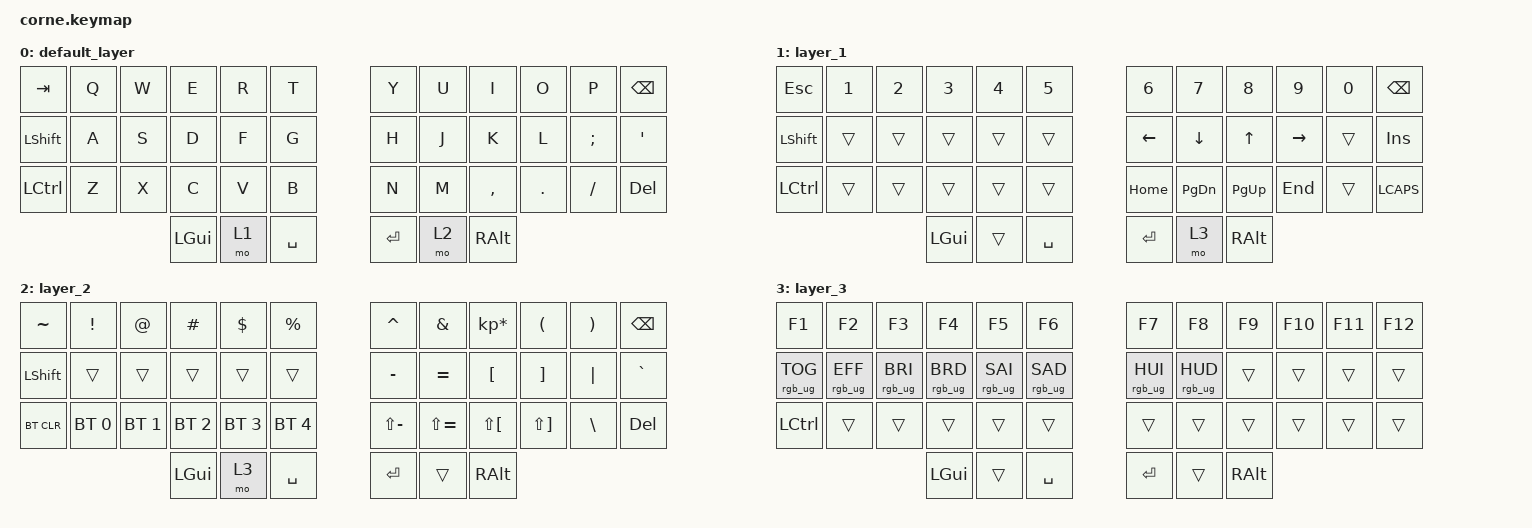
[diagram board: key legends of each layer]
/*
 * Copyright (c) 2020 The ZMK Contributors
 *
 * SPDX-License-Identifier: MIT
 */

#include <behaviors.dtsi>
#include <dt-bindings/zmk/keys.h>
#include <dt-bindings/zmk/bt.h>
#include <dt-bindings/zmk/rgb.h>

/ {
        keymap {
                compatible = "zmk,keymap";

                default_layer {
// -----------------------------------------------------------------------------------------
// | TAB  |  Q  |  W  |  E  |  R  |  T  |   |  Y  |  U   |  I  |  O  |  P  | BKSP |
// | SHFT |  A  |  S  |  D  |  F  |  G  |   |  H  |  J   |  K  |  L  |  ;  |  '   |
// | CTRL |  Z  |  X  |  C  |  V  |  B  |   |  N  |  M   |  ,  |  .  |  /  | DEL  |
//                    | GUI | LWR | SPC |   | ENT | RSE  | ALT |
                        bindings = <
   &kp TAB   &kp Q &kp W &kp E &kp R &kp T   &kp Y &kp U  &kp I     &kp O   &kp P    &kp BSPC
   &kp LSHFT &kp A &kp S &kp D &kp F &kp G   &kp H &kp J  &kp K     &kp L   &kp SEMI &kp SQT
   &kp LCTRL &kp Z &kp X &kp C &kp V &kp B   &kp N &kp M  &kp COMMA &kp DOT &kp FSLH &kp DEL
                  &kp LGUI &mo 1 &kp SPACE   &kp RET &mo 2 &kp RALT
                        >;
                };
                layer_1 {
// -----------------------------------------------------------------------------------------
// | ESC  |  1  |  2  |  3  |  4  |  5  |   |  6  |  7  |  8  |  9  |  0  | BKSP |
// | SHFT |     |     |     |     |     |   | LFT | DWN |  UP | RGT |     | INS  |
// | CTRL |     |     |     |     |     |   | HOME|PG_DN|PG_UP| END |     | LCAPS|
//                    | GUI |     | SPC |   | ENT |  L3 | ALT |
                        bindings = <
   &kp ESC    &kp N1       &kp N2       &kp N3       &kp N4       &kp N5     &kp N6    &kp N7    &kp N8    &kp N9    &kp N0 &kp BSPC
   &kp LSHFT  &trans       &trans       &trans       &trans       &trans     &kp LEFT  &kp DOWN  &kp UP    &kp RIGHT &trans &kp INS
   &kp LCTRL  &trans       &trans       &trans       &trans       &trans     &kp HOME  &kp PG_DN &kp PG_UP &kp END   &trans &kp LCAPS
                                        &kp LGUI     &trans       &kp SPACE  &kp RET   &mo 3     &kp RALT
                        >;
                };

                layer_2 {
// -----------------------------------------------------------------------------------------
// | ESC  |  !  |  @  |  #  |  $  |  %  |   |  ^  |  &  |  *  |  (  |  )  | BKSP |
// | SHFT |     |     |     |     |     |   |  -  |  =  |  {  |  }  | "|" |  `   |
// | BTCLR| BT1 | BT2 | BT3 | BT4 | BT5 |   |  _  |  +  |  [  |  ]  |  \  |  ~   | // TODO: Fix this row when &mkp is committed
//                    | GUI |  L3 | SPC |   | ENT |     | ALT |
                        bindings = <
   &kp TILDE  &kp EXCL     &kp AT       &kp HASH     &kp DLLR     &kp PRCNT         &kp CARET       &kp AMPS      &kp KP_MULTIPLY &kp LPAR    &kp RPAR &kp BSPC
   &kp LSHFT  &trans       &trans       &trans       &trans       &trans            &kp MINUS       &kp EQUAL     &kp LBKT        &kp RBKT    &kp PIPE &kp GRAVE
   &bt BT_CLR &bt BT_SEL 0 &bt BT_SEL 1 &bt BT_SEL 2 &bt BT_SEL 3 &bt BT_SEL 4      &kp LS(MINUS)   &kp LS(EQUAL) &kp LS(LBKT)    &kp LS(RBKT)&kp BSLH &kp DEL
                                        &kp LGUI     &mo 3        &kp SPACE         &kp RET         &trans        &kp RALT
                        >;
                };
                
                
                layer_3 {
// -----------------------------------------------------------------------------------------
// | F1      |  F2     |  F3     |  F4     | F5      | F6      |   |  F7     |  F8     |  F9  |  F10  |  F11  | F12 |
// | RGB_TOG | RGB_EFF | RGB_BRI | RGB_BRD | RGB_SAI | RGB_SAD |   | RGB_HUI | RGB_HUD |      |       |       |     |
// | CTRL    |         |         |         |         |         |   |         |         |      |       |       |     | 
//                               | GUI     |         | SPC     |   | ENT     |         | ALT  |
                        bindings = <
   &kp F1          &kp F2            &kp F3          &kp F4          &kp F5          &kp F6          &kp F7          &kp F8          &kp F9          &kp F10 &kp F11 &kp F12
   &rgb_ug RGB_TOG &rgb_ug RGB_EFF   &rgb_ug RGB_BRI &rgb_ug RGB_BRD &rgb_ug RGB_SAI &rgb_ug RGB_SAD &rgb_ug RGB_HUI &rgb_ug RGB_HUD &trans          &trans  &trans  &trans
   &kp LCTRL       &trans            &trans          &trans          &trans          &trans          &trans          &trans          &trans          &trans  &trans  &trans
                                                     &kp LGUI        &trans          &kp SPACE       &kp RET         &trans          &kp RALT
                        >;
                };
        };
};
